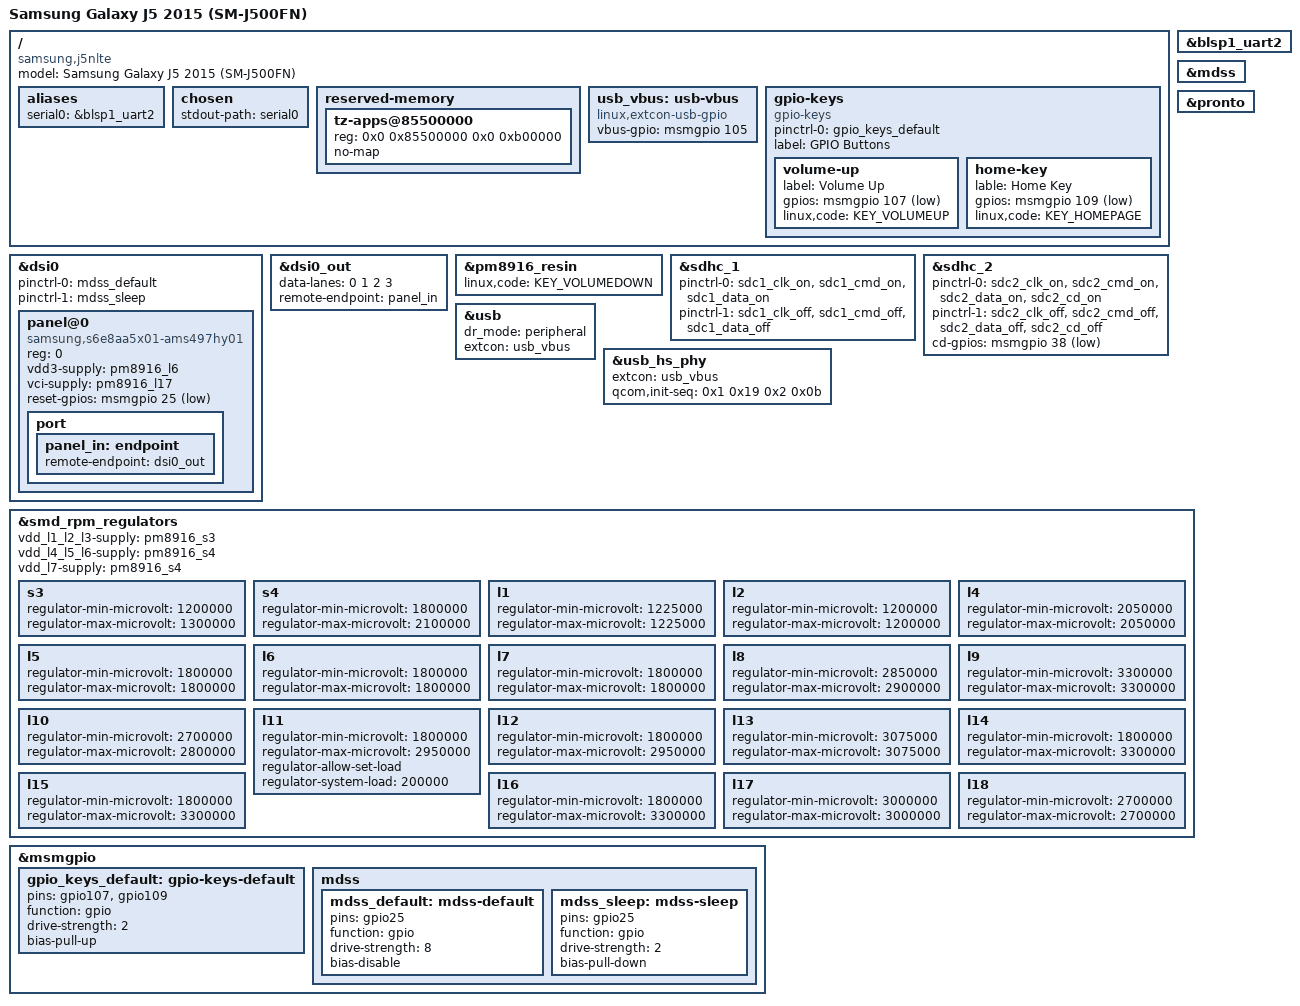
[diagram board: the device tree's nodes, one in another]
// SPDX-License-Identifier: GPL-2.0-only

/dts-v1/;

#include "msm8916-pm8916.dtsi"
#include "arm/qcom-msm8916-no-psci.dtsi"
#include <dt-bindings/gpio/gpio.h>

/ {
	model = "Samsung Galaxy J5 2015 (SM-J500FN)";
	compatible = "samsung,j5nlte", "qcom,msm8916";

	aliases {
		serial0 = &blsp1_uart2;
	};

	chosen {
		stdout-path = "serial0";
	};

	reserved-memory {
		/* Additional memory used by Samsung firmware modifications */
		tz-apps@85500000 {
			reg = <0x0 0x85500000 0x0 0xb00000>;
			no-map;
		};
	};

	// FIXME: Use extcon device provided by MUIC driver when available
	usb_vbus: usb-vbus {
		compatible = "linux,extcon-usb-gpio";
		vbus-gpio = <&msmgpio 105 GPIO_ACTIVE_HIGH>;
	};

	gpio-keys {
		compatible = "gpio-keys";

		pinctrl-names = "default";
		pinctrl-0 = <&gpio_keys_default>;

		label = "GPIO Buttons";

		volume-up {
			label = "Volume Up";
			gpios = <&msmgpio 107 GPIO_ACTIVE_LOW>;
			linux,code = <KEY_VOLUMEUP>;
		};

		home-key {
			lable = "Home Key";
			gpios = <&msmgpio 109 GPIO_ACTIVE_LOW>;
			linux,code = <KEY_HOMEPAGE>;
		};
	};
};

&blsp1_uart2 {
	status = "okay";
};

&dsi0 {
	pinctrl-names = "default", "sleep";
	pinctrl-0 = <&mdss_default>;
	pinctrl-1 = <&mdss_sleep>;

	panel@0 {
		reg = <0>;

		compatible = "samsung,s6e8aa5x01-ams497hy01";

		vdd3-supply = <&pm8916_l6>;
		vci-supply = <&pm8916_l17>;

		reset-gpios = <&msmgpio 25 GPIO_ACTIVE_LOW>;

		port {
			panel_in: endpoint {
				remote-endpoint = <&dsi0_out>;
			};
		};
	};
};

&dsi0_out {
	data-lanes = <0 1 2 3>;
	remote-endpoint = <&panel_in>;
};

&mdss {
	status = "okay";
};

&pm8916_resin {
	status = "okay";
	linux,code = <KEY_VOLUMEDOWN>;
};

&pronto {
	status = "okay";
};

&sdhc_1 {
	status = "okay";

	pinctrl-names = "default", "sleep";
	pinctrl-0 = <&sdc1_clk_on &sdc1_cmd_on &sdc1_data_on>;
	pinctrl-1 = <&sdc1_clk_off &sdc1_cmd_off &sdc1_data_off>;
};

&sdhc_2 {
	status = "okay";

	pinctrl-names = "default", "sleep";
	pinctrl-0 = <&sdc2_clk_on &sdc2_cmd_on &sdc2_data_on &sdc2_cd_on>;
	pinctrl-1 = <&sdc2_clk_off &sdc2_cmd_off &sdc2_data_off &sdc2_cd_off>;

	cd-gpios = <&msmgpio 38 GPIO_ACTIVE_LOW>;
};

&usb {
	status = "okay";
	dr_mode = "peripheral";
	extcon = <&usb_vbus>;
};

&usb_hs_phy {
	extcon = <&usb_vbus>;
	qcom,init-seq = /bits/ 8 <0x1 0x19 0x2 0x0b>;
};

&smd_rpm_regulators {
	vdd_l1_l2_l3-supply = <&pm8916_s3>;
	vdd_l4_l5_l6-supply = <&pm8916_s4>;
	vdd_l7-supply = <&pm8916_s4>;

	s3 {
		regulator-min-microvolt = <1200000>;
		regulator-max-microvolt = <1300000>;
	};

	s4 {
		regulator-min-microvolt = <1800000>;
		regulator-max-microvolt = <2100000>;
	};

	l1 {
		regulator-min-microvolt = <1225000>;
		regulator-max-microvolt = <1225000>;
	};

	l2 {
		regulator-min-microvolt = <1200000>;
		regulator-max-microvolt = <1200000>;
	};

	l4 {
		regulator-min-microvolt = <2050000>;
		regulator-max-microvolt = <2050000>;
	};

	l5 {
		regulator-min-microvolt = <1800000>;
		regulator-max-microvolt = <1800000>;
	};

	l6 {
		regulator-min-microvolt = <1800000>;
		regulator-max-microvolt = <1800000>;
	};

	l7 {
		regulator-min-microvolt = <1800000>;
		regulator-max-microvolt = <1800000>;
	};

	l8 {
		regulator-min-microvolt = <2850000>;
		regulator-max-microvolt = <2900000>;
	};

	l9 {
		regulator-min-microvolt = <3300000>;
		regulator-max-microvolt = <3300000>;
	};

	l10 {
		regulator-min-microvolt = <2700000>;
		regulator-max-microvolt = <2800000>;
	};

	l11 {
		regulator-min-microvolt = <1800000>;
		regulator-max-microvolt = <2950000>;
		regulator-allow-set-load;
		regulator-system-load = <200000>;
	};

	l12 {
		regulator-min-microvolt = <1800000>;
		regulator-max-microvolt = <2950000>;
	};

	l13 {
		regulator-min-microvolt = <3075000>;
		regulator-max-microvolt = <3075000>;
	};

	l14 {
		regulator-min-microvolt = <1800000>;
		regulator-max-microvolt = <3300000>;
	};

	l15 {
		regulator-min-microvolt = <1800000>;
		regulator-max-microvolt = <3300000>;
	};

	l16 {
		regulator-min-microvolt = <1800000>;
		regulator-max-microvolt = <3300000>;
	};

	l17 {
		regulator-min-microvolt = <3000000>;
		regulator-max-microvolt = <3000000>;
	};

	l18 {
		regulator-min-microvolt = <2700000>;
		regulator-max-microvolt = <2700000>;
	};
};

&msmgpio {
	gpio_keys_default: gpio-keys-default {
		pins = "gpio107", "gpio109";
		function = "gpio";

		drive-strength = <2>;
		bias-pull-up;
	};

	mdss {
		mdss_default: mdss-default {
			pins = "gpio25";
			function = "gpio";

			drive-strength = <8>;
			bias-disable;
		};
		mdss_sleep: mdss-sleep {
			pins = "gpio25";
			function = "gpio";

			drive-strength = <2>;
			bias-pull-down;
		};
	};
};
